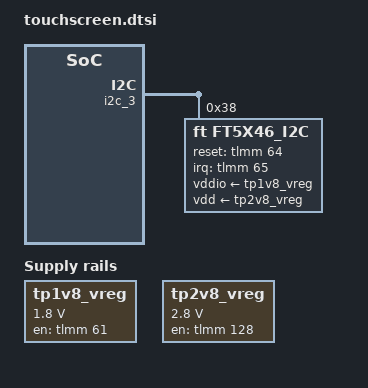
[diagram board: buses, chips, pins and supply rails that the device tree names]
/* msm8953-oxygen.dtsi */

&soc {
	tp1v8_vreg: tp1v8_vreg {
		compatible = "regulator-fixed";
		regulator-name = "tp1v8_vreg";
		regulator-min-microvolt = <1800000>;
		regulator-max-microvolt = <1800000>;
		gpio = <&tlmm 61 0>;
		startup-delay-us = <5000>;
		enable-active-high;
	};
	tp2v8_vreg: tp2v8_vreg {
		compatible = "regulator-fixed";
		regulator-name = "tp2v8_vreg";
		regulator-min-microvolt = <2800000>;
		regulator-max-microvolt = <2800000>;
		gpio = <&tlmm  128 0>;
		startup-delay-us = <5000>;
		enable-active-high;
	};
};

&i2c_3 { /* BLSP1 QUP3 (TP) */
	status = "okay";
	ft5x46_i2c@38 {
		compatible = "ft,ft5x46_i2c";
		reg = <0x38>;
		interrupt-parent = <&tlmm>;
		interrupts = <65 0x2008>;
		vddio-supply = <&tp1v8_vreg>;
		vdd-supply = <&tp2v8_vreg>;
		/* pins used by touchscreen */
		pinctrl-names = "pmx_ts_active","pmx_ts_suspend";
		pinctrl-0 = <&ts_int_active &ts_reset_active>;
		pinctrl-1 = <&ts_int_suspend &ts_reset_suspend>;
		ft5x46_i2c,i2c-pull-up;
		ft5x46_i2c,irqflags = <0x2008>;
		ft5x46_i2c,x-max = <1080>;
		ft5x46_i2c,y-max = <1920>;
		ft5x46_i2c,z-max = <255>;
		ft5x46_i2c,w-max = <200>;
		ft5x46_i2c,reset-gpio = <&tlmm 64 0x00>;
		ft5x46_i2c,irq-gpio = <&tlmm 65 0x2008>;
		ft5x46_i2c,landing-jiffies = <1000>;
		ft5x46_i2c,landing-threshold = <16>;
		ft5x46_i2c,staying-threshold = <8>;
		ft5x46_i2c,raw-min = <7000>;
		ft5x46_i2c,raw-max = <10000>;
		ft5x46_i2c,has-key;
		ft5x46_i2c,key-rx1 = <4>;
		ft5x46_i2c,key-rx2 = <8>;
		ft5x46_i2c,key-rx3 = <12>;
		ft5x46_i2c,open-min = <4000>;
		ft5x46_i2c,imin-cc = <500>;
		ft5x46_i2c,imin-cg = <500>;
		ft5x46_i2c,fw-delay-55-ms = <2>;
		ft5x46_i2c,fw-delay-aa-ms = <2>;
		ft5x46_i2c,fw-upgrade-id1 = <0x54>;
		ft5x46_i2c,fw-upgrade-id2 = <0x2C>;
		ft5x46_i2c,fw-delay-readid-ms = <20>;
		ft5x46_i2c,firmware-array-size = <3>;
		ft5x46_i2c,cfg_0 {
			ft5x46_i2c,chip = <0x54>;
			ft5x46_i2c,vendor = <0x3b>;
			ft5x46_i2c,lcd-vendor = <0x36>;
			ft5x46_i2c,fw-name = "ft5446_biel.fw";
			ft5x46_i2c,tx-num = <24>;
			ft5x46_i2c,rx-num = <13>;
		};
		ft5x46_i2c,cfg_1 {
			ft5x46_i2c,chip = <0x54>;
			ft5x46_i2c,vendor = <0x51>;
			ft5x46_i2c,lcd-vendor = <0x36>;
			ft5x46_i2c,fw-name = "ft5446_ofilm.fw";
			ft5x46_i2c,tx-num = <24>;
			ft5x46_i2c,rx-num = <13>;
		};
		ft5x46_i2c,cfg_2 {
			ft5x46_i2c,chip = <0x54>;
			ft5x46_i2c,vendor = <0x3b>;
			ft5x46_i2c,lcd-vendor = <0x34>;
			ft5x46_i2c,fw-name = "ft5446_biel_auo.fw";
			ft5x46_i2c,tx-num = <24>;
			ft5x46_i2c,rx-num = <13>;
		};
	};
};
